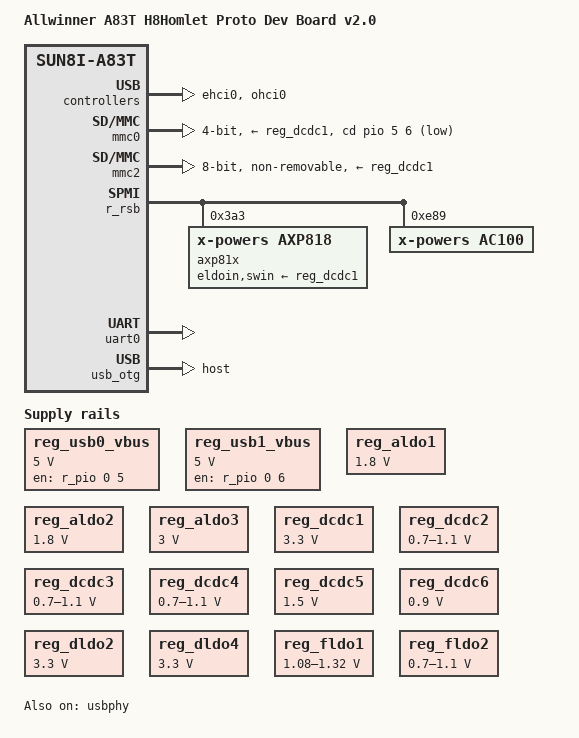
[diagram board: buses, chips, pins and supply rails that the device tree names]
/dts-v1/;
#include "sun8i-a83t.dtsi"
#include <dt-bindings/gpio/gpio.h>
/ {
	model = "Allwinner A83T H8Homlet Proto Dev Board v2.0";
	compatible = "allwinner,h8homlet-v2", "allwinner,sun8i-a83t";
	aliases {
		serial0 = &uart0;
	};
	chosen {
		stdout-path = "serial0:115200n8";
	};
	reg_usb0_vbus: reg-usb0-vbus {
		compatible = "regulator-fixed";
		regulator-name = "usb0-vbus";
		regulator-min-microvolt = <5000000>;
		regulator-max-microvolt = <5000000>;
		regulator-boot-on;
		enable-active-high;
		gpio = <&r_pio 0 5 GPIO_ACTIVE_HIGH>;  
	};
	reg_usb1_vbus: reg-usb1-vbus {
		compatible = "regulator-fixed";
		regulator-name = "usb1-vbus";
		regulator-min-microvolt = <5000000>;
		regulator-max-microvolt = <5000000>;
		regulator-boot-on;
		enable-active-high;
		gpio = <&r_pio 0 6 GPIO_ACTIVE_HIGH>;  
	};
};
&cpu0 {
	cpu-supply = <&reg_dcdc2>;
};
&cpu100 {
	cpu-supply = <&reg_dcdc3>;
};
&ehci0 {
	status = "okay";
};
&mmc0 {
	pinctrl-names = "default";
	pinctrl-0 = <&mmc0_pins>;
	vmmc-supply = <&reg_dcdc1>;
	cd-gpios = <&pio 5 6 GPIO_ACTIVE_LOW>;  
	bus-width = <4>;
	status = "okay";
};
&mmc2 {
	pinctrl-names = "default";
	pinctrl-0 = <&mmc2_8bit_emmc_pins>;
	vmmc-supply = <&reg_dcdc1>;
	vqmmc-supply = <&reg_dcdc1>;
	bus-width = <8>;
	non-removable;
	cap-mmc-hw-reset;
	status = "okay";
};
&ohci0 {
	status = "okay";
};
&r_rsb {
	status = "okay";
	axp81x: pmic@3a3 {
		compatible = "x-powers,axp818", "x-powers,axp813";
		reg = <0x3a3>;
		interrupt-parent = <&r_intc>;
		interrupts = <GIC_SPI 32 IRQ_TYPE_LEVEL_LOW>;
		eldoin-supply = <&reg_dcdc1>;
		swin-supply = <&reg_dcdc1>;
	};
	ac100: codec@e89 {
		compatible = "x-powers,ac100";
		reg = <0xe89>;
		ac100_codec: codec {
			compatible = "x-powers,ac100-codec";
			interrupt-parent = <&r_pio>;
			interrupts = <0 11 IRQ_TYPE_LEVEL_LOW>;  
			#clock-cells = <0>;
			clock-output-names = "4M_adda";
		};
		ac100_rtc: rtc {
			compatible = "x-powers,ac100-rtc";
			interrupt-parent = <&r_intc>;
			interrupts = <GIC_SPI 32 IRQ_TYPE_LEVEL_LOW>;
			clocks = <&ac100_codec>;
			#clock-cells = <1>;
			clock-output-names = "cko1_rtc",
					     "cko2_rtc",
					     "cko3_rtc";
		};
	};
};
#include "axp81x.dtsi"
&ac_power_supply {
	status = "okay";
};
&reg_aldo1 {
	regulator-always-on;
	regulator-min-microvolt = <1800000>;
	regulator-max-microvolt = <1800000>;
	regulator-name = "vcc-1v8";
};
&reg_aldo2 {
	regulator-always-on;
	regulator-min-microvolt = <1800000>;
	regulator-max-microvolt = <1800000>;
	regulator-name = "dram-pll";
};
&reg_aldo3 {
	regulator-always-on;
	regulator-min-microvolt = <3000000>;
	regulator-max-microvolt = <3000000>;
	regulator-name = "avcc";
};
&reg_dcdc1 {
	regulator-always-on;
	regulator-min-microvolt = <3300000>;
	regulator-max-microvolt = <3300000>;
	regulator-name = "vcc-3v3";
};
&reg_dcdc2 {
	regulator-always-on;
	regulator-min-microvolt = <700000>;
	regulator-max-microvolt = <1100000>;
	regulator-name = "vdd-cpua";
};
&reg_dcdc3 {
	regulator-always-on;
	regulator-min-microvolt = <700000>;
	regulator-max-microvolt = <1100000>;
	regulator-name = "vdd-cpub";
};
&reg_dcdc4 {
	regulator-min-microvolt = <700000>;
	regulator-max-microvolt = <1100000>;
	regulator-name = "vdd-gpu";
};
&reg_dcdc5 {
	regulator-always-on;
	regulator-min-microvolt = <1500000>;
	regulator-max-microvolt = <1500000>;
	regulator-name = "vcc-dram";
};
&reg_dcdc6 {
	regulator-always-on;
	regulator-min-microvolt = <900000>;
	regulator-max-microvolt = <900000>;
	regulator-name = "vdd-sys";
};
&reg_dldo2 {
	regulator-min-microvolt = <3300000>;
	regulator-max-microvolt = <3300000>;
	regulator-name = "vcc-mipi";
};
&reg_dldo4 {
	regulator-enable-ramp-delay = <100000>;
	regulator-min-microvolt = <3300000>;
	regulator-max-microvolt = <3300000>;
	regulator-name = "vcc-ephy";
};
&reg_fldo1 {
	regulator-min-microvolt = <1080000>;
	regulator-max-microvolt = <1320000>;
	regulator-name = "vdd12-hsic";
};
&reg_fldo2 {
	regulator-always-on;
	regulator-min-microvolt = <700000>;
	regulator-max-microvolt = <1100000>;
	regulator-name = "vdd-cpus";
};
&reg_rtc_ldo {
	regulator-name = "vcc-rtc";
};
&reg_sw {
	regulator-name = "vcc-wifi";
};
&uart0 {
	pinctrl-names = "default";
	pinctrl-0 = <&uart0_pb_pins>;
	status = "okay";
};
&usbphy {
	usb0_vbus-supply = <&reg_usb0_vbus>;
	usb1_vbus-supply = <&reg_usb1_vbus>;
	status = "okay";
};
&usb_otg {
	dr_mode = "host";
	status = "okay";
};
